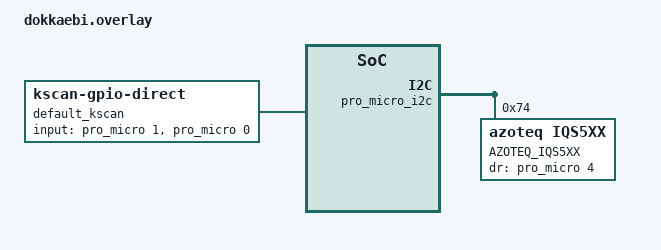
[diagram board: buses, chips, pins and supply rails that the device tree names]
#include <dt-bindings/zmk/trackball_pim447.h> // for PIM447_MOVE and PIM447_SCROLL constants

/ {
    chosen {
        zmk,kscan = &default_kscan;
    };

    default_kscan: kscan {
        compatible = "zmk,kscan-gpio-direct";
        label = "default_kscan";

        input-gpios
            = <&pro_micro 1 GPIO_ACTIVE_HIGH>
            , <&pro_micro 0 GPIO_ACTIVE_HIGH>
            ;
    };
};

&pro_micro_i2c {
	status = "okay";

	trackpad: trackpad@74 {
        compatible = "azoteq,iqs5xx";
        label = "AZOTEQ_IQS5XX";
        status = "okay";
        reg = <0x74>;
        dr-gpios = <&pro_micro 4 GPIO_ACTIVE_HIGH>;
	};
};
